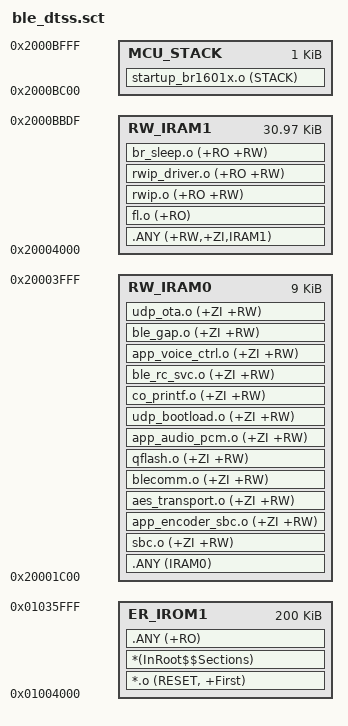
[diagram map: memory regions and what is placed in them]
; *** Scatter-Loading Description File generated by uVision ***
; *************************************************************

LR_IROM1 0x01004000 0x00032000    {    ; APP1 @ 0x01004000, 200KB
  ER_IROM1 0x01004000 0x00032000  {    ; load address = execution address
   *.o (RESET, +First)
   *(InRoot$$Sections)
   .ANY (+RO)
  }
  RW_IRAM0 0x20001C00 0x00002400  {    ; RW data 0 (9 KB：语音/AES + qflash + PCM DMA)
    .ANY (IRAM0)
    sbc.o (+ZI +RW)
    app_encoder_sbc.o (+ZI +RW)
    aes_transport.o (+ZI +RW)
    blecomm.o (+ZI +RW)
    qflash.o (+ZI +RW)
    app_audio_pcm.o (+ZI +RW)
    udp_bootload.o (+ZI +RW)
    co_printf.o (+ZI +RW)
    ble_rc_svc.o (+ZI +RW)
    app_voice_ctrl.o (+ZI +RW)
    ble_gap.o (+ZI +RW)
    udp_ota.o (+ZI +RW)
  }
  RW_IRAM1 0x20004000 0x00007BE0  {    ; stop before crash record @ BBE0
   .ANY (+RW,+ZI,IRAM1)
   fl.o (+RO)
   rwip.o (+RO +RW)
   rwip_driver.o (+RO +RW)
   br_sleep.o (+RO +RW)
  }
  ; Main/ISR stack remains 1KB, fixed above the 32-byte crash record.
  ; No heap or BLE-task stack reduction is needed for the new sleep routines.
  MCU_STACK 0x2000BC00 0x00000400 {
    startup_br1601x.o (STACK)
  }

}

